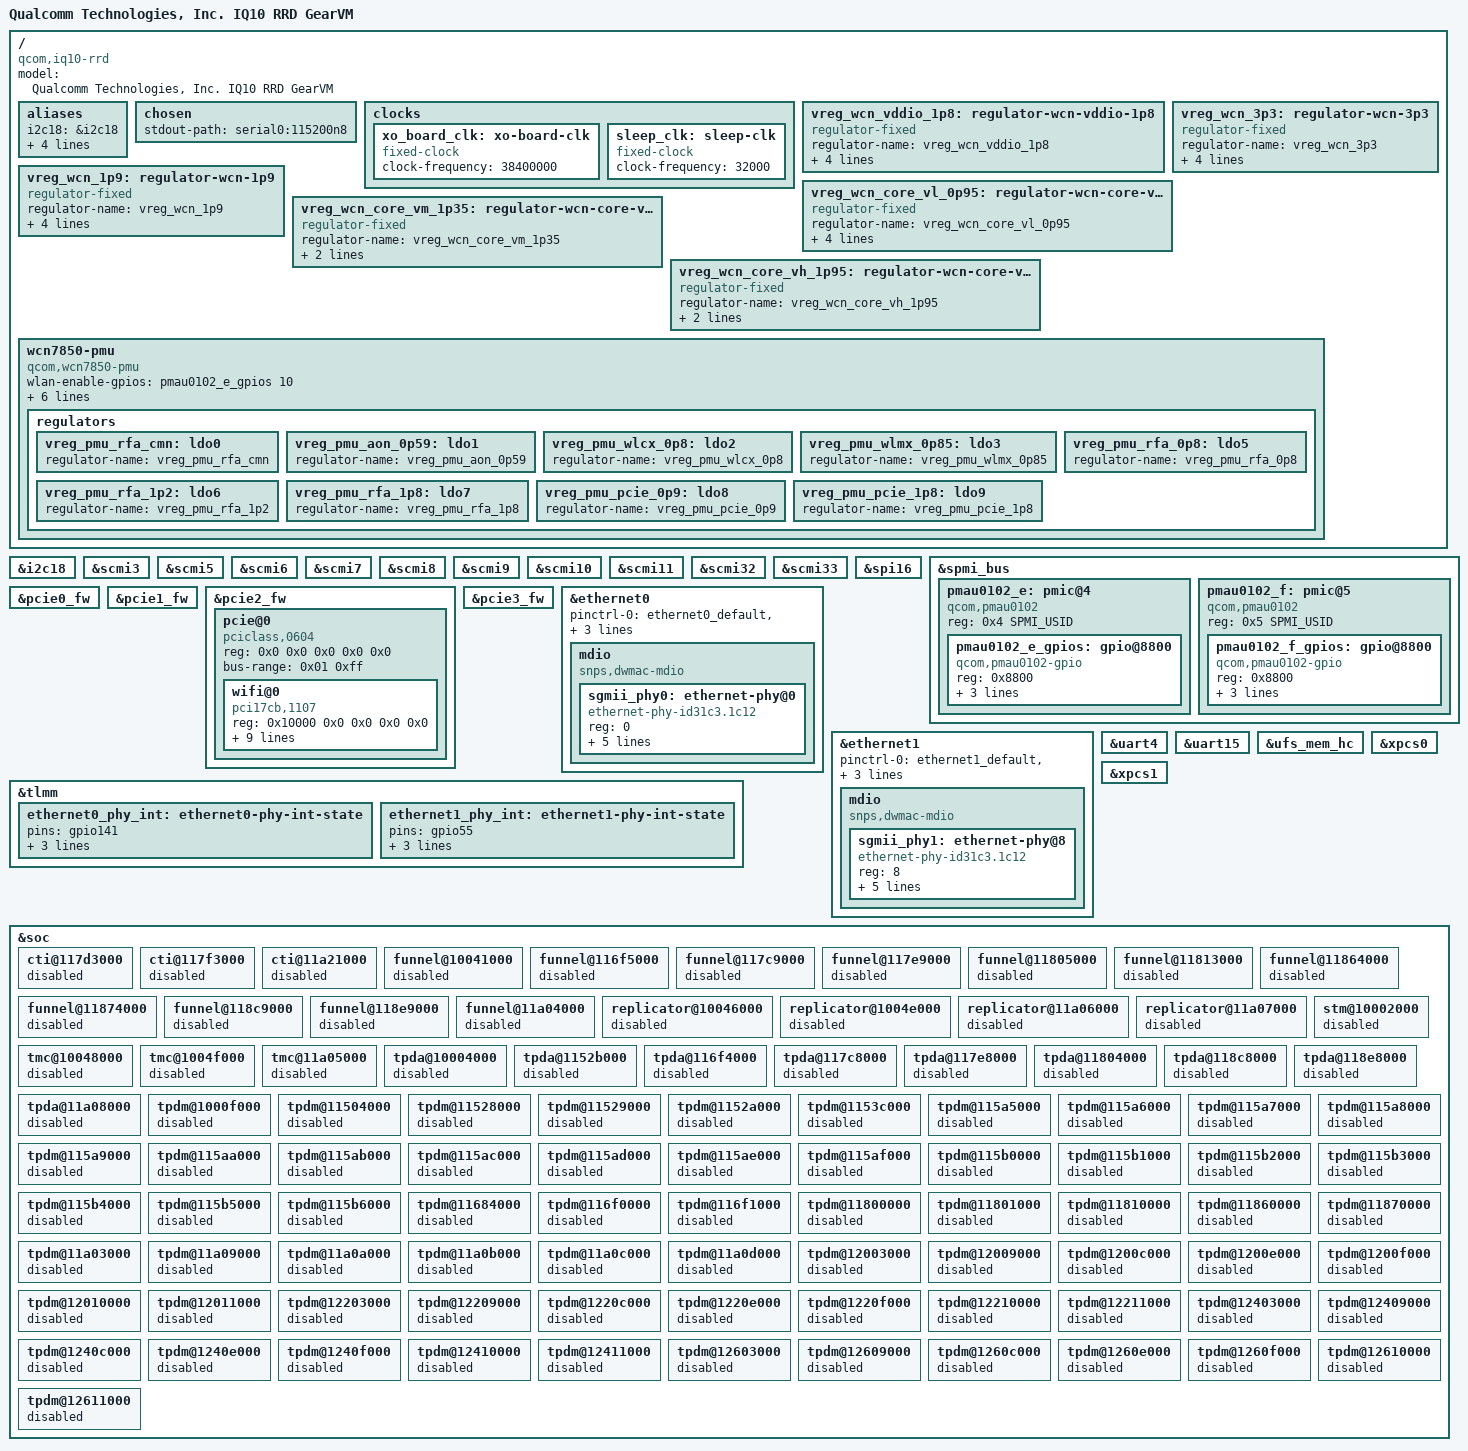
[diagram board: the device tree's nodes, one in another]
// SPDX-License-Identifier: BSD-3-Clause
/*
 * Copyright (c) Qualcomm Technologies, Inc. and/or its subsidiaries.
 */

/dts-v1/;

#include <dt-bindings/gpio/gpio.h>
#include <dt-bindings/interrupt-controller/irq.h>
#include <dt-bindings/spmi/spmi.h>

#include "nord-gearvm.dtsi"

/ {
	model = "Qualcomm Technologies, Inc. IQ10 RRD GearVM";
	compatible = "qcom,iq10-rrd", "qcom,nord";

	aliases {
		i2c18 = &i2c18;
		scmichannels = &reserved_memory;
		serial0 = &uart15;
		serial1 = &uart4;
		spi16 = &spi16;
	};

	chosen {
		stdout-path = "serial0:115200n8";
	};

	clocks {
		xo_board_clk: xo-board-clk {
			compatible = "fixed-clock";
			clock-frequency = <38400000>;
			#clock-cells = <0>;
		};

		sleep_clk: sleep-clk {
			compatible = "fixed-clock";
			clock-frequency = <32000>;
			#clock-cells = <0>;
		};
	};

	vreg_wcn_vddio_1p8: regulator-wcn-vddio-1p8 {
		compatible = "regulator-fixed";
		regulator-name = "vreg_wcn_vddio_1p8";
		regulator-min-microvolt = <1800000>;
		regulator-max-microvolt = <1800000>;
		regulator-always-on;
		regulator-boot-on;
	};

	vreg_wcn_3p3: regulator-wcn-3p3 {
		compatible = "regulator-fixed";
		regulator-name = "vreg_wcn_3p3";
		regulator-min-microvolt = <3300000>;
		regulator-max-microvolt = <3300000>;
		gpio = <&pmau0102_e_gpios 8 GPIO_ACTIVE_HIGH>;
		enable-active-high;
	};

	vreg_wcn_1p9: regulator-wcn-1p9 {
		compatible = "regulator-fixed";
		regulator-name = "vreg_wcn_1p9";
		regulator-min-microvolt = <1900000>;
		regulator-max-microvolt = <1900000>;
		gpio = <&pmau0102_e_gpios 7 GPIO_ACTIVE_HIGH>;
		enable-active-high;
	};

	/* PWR_CORE enables the VL, VM and VH core rails. */
	vreg_wcn_core_vl_0p95: regulator-wcn-core-vl-0p95 {
		compatible = "regulator-fixed";
		regulator-name = "vreg_wcn_core_vl_0p95";
		regulator-min-microvolt = <950000>;
		regulator-max-microvolt = <950000>;
		gpio = <&pmau0102_e_gpios 6 GPIO_ACTIVE_HIGH>;
		enable-active-high;
	};

	vreg_wcn_core_vm_1p35: regulator-wcn-core-vm-1p35 {
		compatible = "regulator-fixed";
		regulator-name = "vreg_wcn_core_vm_1p35";
		regulator-min-microvolt = <1350000>;
		regulator-max-microvolt = <1350000>;
	};

	vreg_wcn_core_vh_1p95: regulator-wcn-core-vh-1p95 {
		compatible = "regulator-fixed";
		regulator-name = "vreg_wcn_core_vh_1p95";
		regulator-min-microvolt = <1950000>;
		regulator-max-microvolt = <1950000>;
	};

	wcn7850-pmu {
		compatible = "qcom,wcn7850-pmu";

		wlan-enable-gpios = <&pmau0102_e_gpios 10 GPIO_ACTIVE_HIGH>;

		vdd-supply = <&vreg_wcn_3p3>;
		vddio-supply = <&vreg_wcn_vddio_1p8>;
		vddaon-supply = <&vreg_wcn_core_vl_0p95>;
		vdddig-supply = <&vreg_wcn_1p9>;
		vddrfa1p2-supply = <&vreg_wcn_core_vm_1p35>;
		vddrfa1p8-supply = <&vreg_wcn_core_vh_1p95>;

		regulators {
			vreg_pmu_rfa_cmn: ldo0 {
				regulator-name = "vreg_pmu_rfa_cmn";
			};

			vreg_pmu_aon_0p59: ldo1 {
				regulator-name = "vreg_pmu_aon_0p59";
			};

			vreg_pmu_wlcx_0p8: ldo2 {
				regulator-name = "vreg_pmu_wlcx_0p8";
			};

			vreg_pmu_wlmx_0p85: ldo3 {
				regulator-name = "vreg_pmu_wlmx_0p85";
			};

			vreg_pmu_rfa_0p8: ldo5 {
				regulator-name = "vreg_pmu_rfa_0p8";
			};

			vreg_pmu_rfa_1p2: ldo6 {
				regulator-name = "vreg_pmu_rfa_1p2";
			};

			vreg_pmu_rfa_1p8: ldo7 {
				regulator-name = "vreg_pmu_rfa_1p8";
			};

			vreg_pmu_pcie_0p9: ldo8 {
				regulator-name = "vreg_pmu_pcie_0p9";
			};

			vreg_pmu_pcie_1p8: ldo9 {
				regulator-name = "vreg_pmu_pcie_1p8";
			};
		};
	};
};

&i2c18 {
	status = "okay";
};

&scmi3 {
	status = "okay";
};

&scmi5 {
	status = "okay";
};

&scmi6 {
	status = "okay";
};

&scmi7 {
	status = "okay";
};

&scmi8 {
	status = "okay";
};

&scmi9 {
	status = "okay";
};

&scmi10 {
	status = "okay";
};

&scmi11 {
	status = "okay";
};

&scmi32 {
	status = "okay";
};

&scmi33 {
	status = "okay";
};

&spi16 {
	status = "okay";
};

&spmi_bus {
	pmau0102_e: pmic@4 {
		compatible = "qcom,pmau0102", "qcom,spmi-pmic";
		reg = <0x4 SPMI_USID>;
		#address-cells = <1>;
		#size-cells = <0>;

		pmau0102_e_gpios: gpio@8800 {
			compatible = "qcom,pmau0102-gpio", "qcom,spmi-gpio";
			reg = <0x8800>;
			gpio-controller;
			gpio-ranges = <&pmau0102_e_gpios 0 0 12>;
			#gpio-cells = <2>;
			interrupt-controller;
			#interrupt-cells = <2>;
		};
	};

	pmau0102_f: pmic@5 {
		compatible = "qcom,pmau0102", "qcom,spmi-pmic";
		reg = <0x5 SPMI_USID>;
		#address-cells = <1>;
		#size-cells = <0>;

		pmau0102_f_gpios: gpio@8800 {
			compatible = "qcom,pmau0102-gpio", "qcom,spmi-gpio";
			reg = <0x8800>;
			gpio-controller;
			gpio-ranges = <&pmau0102_f_gpios 0 0 12>;
			#gpio-cells = <2>;
			interrupt-controller;
			#interrupt-cells = <2>;
		};
	};
};

&pcie0_fw {
	status = "okay";
};

&pcie1_fw {
	status = "okay";
};

&pcie2_fw {
	status = "okay";

	pcie@0 {
		compatible = "pciclass,0604";
		reg = <0x0 0x0 0x0 0x0 0x0>;
		bus-range = <0x01 0xff>;
		device_type = "pci";
		#address-cells = <3>;
		#size-cells = <2>;
		ranges;

		wifi@0 {
			compatible = "pci17cb,1107";
			reg = <0x10000 0x0 0x0 0x0 0x0>;

			vddaon-supply = <&vreg_pmu_aon_0p59>;
			vddwlcx-supply = <&vreg_pmu_wlcx_0p8>;
			vddwlmx-supply = <&vreg_pmu_wlmx_0p85>;
			vddrfacmn-supply = <&vreg_pmu_rfa_cmn>;
			vddrfa0p8-supply = <&vreg_pmu_rfa_0p8>;
			vddrfa1p2-supply = <&vreg_pmu_rfa_1p2>;
			vddrfa1p8-supply = <&vreg_pmu_rfa_1p8>;
			vddpcie0p9-supply = <&vreg_pmu_pcie_0p9>;
			vddpcie1p8-supply = <&vreg_pmu_pcie_1p8>;
		};
	};
};

&pcie3_fw {
	status = "okay";
};

&ethernet0 {
	pinctrl-0 = <&ethernet0_default>, <&ethernet0_phy_int>;
	pinctrl-names = "default";

	phy-mode = "usxgmii";
	phy-handle = <&sgmii_phy0>;

	status = "okay";

	mdio {
		compatible = "snps,dwmac-mdio";
		#address-cells = <1>;
		#size-cells = <0>;

		sgmii_phy0: ethernet-phy@0 {
			compatible = "ethernet-phy-id31c3.1c12";
			reg = <0>;
			interrupts-extended = <&tlmm 141 IRQ_TYPE_EDGE_FALLING>;
			reset-gpios = <&pmau0102_e_gpios 5 GPIO_ACTIVE_LOW>;
			reset-assert-us = <11000>;
			reset-deassert-us = <70000>;
		};
	};
};

&ethernet1 {
	pinctrl-0 = <&ethernet1_default>, <&ethernet1_phy_int>;
	pinctrl-names = "default";

	phy-mode = "usxgmii";
	phy-handle = <&sgmii_phy1>;

	status = "okay";

	mdio {
		compatible = "snps,dwmac-mdio";
		#address-cells = <1>;
		#size-cells = <0>;

		sgmii_phy1: ethernet-phy@8 {
			compatible = "ethernet-phy-id31c3.1c12";
			reg = <8>;
			interrupts-extended = <&tlmm 55 IRQ_TYPE_EDGE_FALLING>;
			reset-gpios = <&pmau0102_f_gpios 7 GPIO_ACTIVE_LOW>;
			reset-assert-us = <11000>;
			reset-deassert-us = <70000>;
		};
	};
};

&tlmm {
	ethernet0_phy_int: ethernet0-phy-int-state {
		pins = "gpio141";
		function = "gpio";
		drive-strength = <2>;
		bias-pull-up;
	};

	ethernet1_phy_int: ethernet1-phy-int-state {
		pins = "gpio55";
		function = "gpio";
		drive-strength = <2>;
		bias-pull-up;
	};
};

&uart4 {
	status = "okay";
};

&uart15 {
	status = "okay";
};

&ufs_mem_hc {
	status = "okay";
};

&xpcs0 {
	status = "okay";
};

&xpcs1 {
	status = "okay";
};

/* The RRD firmware does not expose the CoreSight PrimeCell registers. */
&soc {
	cti@117d3000 { status = "disabled"; };
	cti@117f3000 { status = "disabled"; };
	cti@11a21000 { status = "disabled"; };
	funnel@10041000 { status = "disabled"; };
	funnel@116f5000 { status = "disabled"; };
	funnel@117c9000 { status = "disabled"; };
	funnel@117e9000 { status = "disabled"; };
	funnel@11805000 { status = "disabled"; };
	funnel@11813000 { status = "disabled"; };
	funnel@11864000 { status = "disabled"; };
	funnel@11874000 { status = "disabled"; };
	funnel@118c9000 { status = "disabled"; };
	funnel@118e9000 { status = "disabled"; };
	funnel@11a04000 { status = "disabled"; };
	replicator@10046000 { status = "disabled"; };
	replicator@1004e000 { status = "disabled"; };
	replicator@11a06000 { status = "disabled"; };
	replicator@11a07000 { status = "disabled"; };
	stm@10002000 { status = "disabled"; };
	tmc@10048000 { status = "disabled"; };
	tmc@1004f000 { status = "disabled"; };
	tmc@11a05000 { status = "disabled"; };
	tpda@10004000 { status = "disabled"; };
	tpda@1152b000 { status = "disabled"; };
	tpda@116f4000 { status = "disabled"; };
	tpda@117c8000 { status = "disabled"; };
	tpda@117e8000 { status = "disabled"; };
	tpda@11804000 { status = "disabled"; };
	tpda@118c8000 { status = "disabled"; };
	tpda@118e8000 { status = "disabled"; };
	tpda@11a08000 { status = "disabled"; };
	tpdm@1000f000 { status = "disabled"; };
	tpdm@11504000 { status = "disabled"; };
	tpdm@11528000 { status = "disabled"; };
	tpdm@11529000 { status = "disabled"; };
	tpdm@1152a000 { status = "disabled"; };
	tpdm@1153c000 { status = "disabled"; };
	tpdm@115a5000 { status = "disabled"; };
	tpdm@115a6000 { status = "disabled"; };
	tpdm@115a7000 { status = "disabled"; };
	tpdm@115a8000 { status = "disabled"; };
	tpdm@115a9000 { status = "disabled"; };
	tpdm@115aa000 { status = "disabled"; };
	tpdm@115ab000 { status = "disabled"; };
	tpdm@115ac000 { status = "disabled"; };
	tpdm@115ad000 { status = "disabled"; };
	tpdm@115ae000 { status = "disabled"; };
	tpdm@115af000 { status = "disabled"; };
	tpdm@115b0000 { status = "disabled"; };
	tpdm@115b1000 { status = "disabled"; };
	tpdm@115b2000 { status = "disabled"; };
	tpdm@115b3000 { status = "disabled"; };
	tpdm@115b4000 { status = "disabled"; };
	tpdm@115b5000 { status = "disabled"; };
	tpdm@115b6000 { status = "disabled"; };
	tpdm@11684000 { status = "disabled"; };
	tpdm@116f0000 { status = "disabled"; };
	tpdm@116f1000 { status = "disabled"; };
	tpdm@11800000 { status = "disabled"; };
	tpdm@11801000 { status = "disabled"; };
	tpdm@11810000 { status = "disabled"; };
	tpdm@11860000 { status = "disabled"; };
	tpdm@11870000 { status = "disabled"; };
	tpdm@11a03000 { status = "disabled"; };
	tpdm@11a09000 { status = "disabled"; };
	tpdm@11a0a000 { status = "disabled"; };
	tpdm@11a0b000 { status = "disabled"; };
	tpdm@11a0c000 { status = "disabled"; };
	tpdm@11a0d000 { status = "disabled"; };
	tpdm@12003000 { status = "disabled"; };
	tpdm@12009000 { status = "disabled"; };
	tpdm@1200c000 { status = "disabled"; };
	tpdm@1200e000 { status = "disabled"; };
	tpdm@1200f000 { status = "disabled"; };
	tpdm@12010000 { status = "disabled"; };
	tpdm@12011000 { status = "disabled"; };
	tpdm@12203000 { status = "disabled"; };
	tpdm@12209000 { status = "disabled"; };
	tpdm@1220c000 { status = "disabled"; };
	tpdm@1220e000 { status = "disabled"; };
	tpdm@1220f000 { status = "disabled"; };
	tpdm@12210000 { status = "disabled"; };
	tpdm@12211000 { status = "disabled"; };
	tpdm@12403000 { status = "disabled"; };
	tpdm@12409000 { status = "disabled"; };
	tpdm@1240c000 { status = "disabled"; };
	tpdm@1240e000 { status = "disabled"; };
	tpdm@1240f000 { status = "disabled"; };
	tpdm@12410000 { status = "disabled"; };
	tpdm@12411000 { status = "disabled"; };
	tpdm@12603000 { status = "disabled"; };
	tpdm@12609000 { status = "disabled"; };
	tpdm@1260c000 { status = "disabled"; };
	tpdm@1260e000 { status = "disabled"; };
	tpdm@1260f000 { status = "disabled"; };
	tpdm@12610000 { status = "disabled"; };
	tpdm@12611000 { status = "disabled"; };
};

/* The RRD firmware does not expose the CoreSight PrimeCell registers. */
&soc {
	cti@117d3000 { status = "disabled"; };
	cti@117f3000 { status = "disabled"; };
	cti@11a21000 { status = "disabled"; };
	funnel@10041000 { status = "disabled"; };
	funnel@116f5000 { status = "disabled"; };
	funnel@117c9000 { status = "disabled"; };
	funnel@117e9000 { status = "disabled"; };
	funnel@11805000 { status = "disabled"; };
	funnel@11813000 { status = "disabled"; };
	funnel@11864000 { status = "disabled"; };
	funnel@11874000 { status = "disabled"; };
	funnel@118c9000 { status = "disabled"; };
	funnel@118e9000 { status = "disabled"; };
	funnel@11a04000 { status = "disabled"; };
	replicator@10046000 { status = "disabled"; };
	replicator@1004e000 { status = "disabled"; };
	replicator@11a06000 { status = "disabled"; };
	replicator@11a07000 { status = "disabled"; };
	stm@10002000 { status = "disabled"; };
	tmc@10048000 { status = "disabled"; };
	tmc@1004f000 { status = "disabled"; };
	tmc@11a05000 { status = "disabled"; };
	tpda@10004000 { status = "disabled"; };
	tpda@1152b000 { status = "disabled"; };
	tpda@116f4000 { status = "disabled"; };
	tpda@117c8000 { status = "disabled"; };
	tpda@117e8000 { status = "disabled"; };
	tpda@11804000 { status = "disabled"; };
	tpda@118c8000 { status = "disabled"; };
	tpda@118e8000 { status = "disabled"; };
	tpda@11a08000 { status = "disabled"; };
	tpdm@1000f000 { status = "disabled"; };
	tpdm@11504000 { status = "disabled"; };
	tpdm@11528000 { status = "disabled"; };
	tpdm@11529000 { status = "disabled"; };
	tpdm@1152a000 { status = "disabled"; };
	tpdm@1153c000 { status = "disabled"; };
	tpdm@115a5000 { status = "disabled"; };
	tpdm@115a6000 { status = "disabled"; };
	tpdm@115a7000 { status = "disabled"; };
	tpdm@115a8000 { status = "disabled"; };
	tpdm@115a9000 { status = "disabled"; };
	tpdm@115aa000 { status = "disabled"; };
	tpdm@115ab000 { status = "disabled"; };
	tpdm@115ac000 { status = "disabled"; };
	tpdm@115ad000 { status = "disabled"; };
	tpdm@115ae000 { status = "disabled"; };
	tpdm@115af000 { status = "disabled"; };
	tpdm@115b0000 { status = "disabled"; };
	tpdm@115b1000 { status = "disabled"; };
	tpdm@115b2000 { status = "disabled"; };
	tpdm@115b3000 { status = "disabled"; };
	tpdm@115b4000 { status = "disabled"; };
	tpdm@115b5000 { status = "disabled"; };
	tpdm@115b6000 { status = "disabled"; };
	tpdm@11684000 { status = "disabled"; };
	tpdm@116f0000 { status = "disabled"; };
	tpdm@116f1000 { status = "disabled"; };
	tpdm@11800000 { status = "disabled"; };
	tpdm@11801000 { status = "disabled"; };
	tpdm@11810000 { status = "disabled"; };
	tpdm@11860000 { status = "disabled"; };
	tpdm@11870000 { status = "disabled"; };
	tpdm@11a03000 { status = "disabled"; };
	tpdm@11a09000 { status = "disabled"; };
	tpdm@11a0a000 { status = "disabled"; };
	tpdm@11a0b000 { status = "disabled"; };
	tpdm@11a0c000 { status = "disabled"; };
	tpdm@11a0d000 { status = "disabled"; };
	tpdm@12003000 { status = "disabled"; };
	tpdm@12009000 { status = "disabled"; };
	tpdm@1200c000 { status = "disabled"; };
	tpdm@1200e000 { status = "disabled"; };
	tpdm@1200f000 { status = "disabled"; };
	tpdm@12010000 { status = "disabled"; };
	tpdm@12011000 { status = "disabled"; };
	tpdm@12203000 { status = "disabled"; };
	tpdm@12209000 { status = "disabled"; };
	tpdm@1220c000 { status = "disabled"; };
	tpdm@1220e000 { status = "disabled"; };
	tpdm@1220f000 { status = "disabled"; };
	tpdm@12210000 { status = "disabled"; };
	tpdm@12211000 { status = "disabled"; };
	tpdm@12403000 { status = "disabled"; };
	tpdm@12409000 { status = "disabled"; };
	tpdm@1240c000 { status = "disabled"; };
	tpdm@1240e000 { status = "disabled"; };
	tpdm@1240f000 { status = "disabled"; };
	tpdm@12410000 { status = "disabled"; };
	tpdm@12411000 { status = "disabled"; };
	tpdm@12603000 { status = "disabled"; };
	tpdm@12609000 { status = "disabled"; };
	tpdm@1260c000 { status = "disabled"; };
	tpdm@1260e000 { status = "disabled"; };
	tpdm@1260f000 { status = "disabled"; };
	tpdm@12610000 { status = "disabled"; };
	tpdm@12611000 { status = "disabled"; };
};
